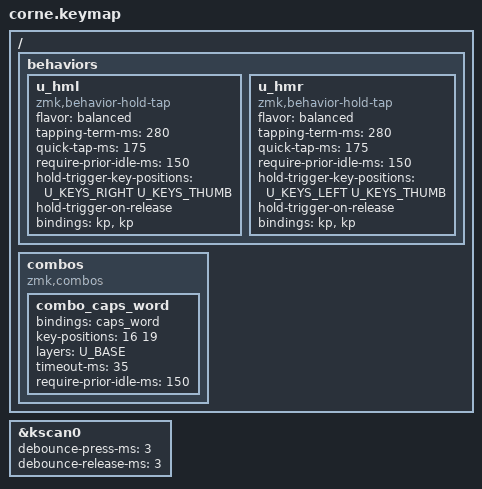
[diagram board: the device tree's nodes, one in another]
#include "../miryoku/custom_config.h"
#include "../miryoku/mapping/42/corne.h"
#include "../miryoku/miryoku.dtsi"

&kscan0 {
  debounce-press-ms = <3>;
  debounce-release-ms = <3>;
};

// Corne key positions, 42 keys, numbered from the top left.
//   0  1  2  3  4  5  |  6  7  8  9 10 11
//  12 13 14 15 16 17  | 18 19 20 21 22 23
//  24 25 26 27 28 29  | 30 31 32 33 34 35
//           36 37 38  | 39 40 41
#define U_KEYS_LEFT   0  1  2  3  4  5 12 13 14 15 16 17 24 25 26 27 28 29
#define U_KEYS_RIGHT  6  7  8  9 10 11 18 19 20 21 22 23 30 31 32 33 34 35
#define U_KEYS_THUMB 36 37 38 39 40 41

// Home-row mods, one behavior per hand. A mod only triggers if the next key is
// on the other hand or on a thumb, so a same-hand roll can never make a mod.
// This removes most false mods, which makes the longer tapping term safe.
// hold-trigger-on-release keeps same-hand mod combinations (such as Cmd+Shift)
// available if you hold both keys.
/ {
  behaviors {
    u_hml: u_hml {
      compatible = "zmk,behavior-hold-tap";
      #binding-cells = <2>;
      flavor = "balanced";
      tapping-term-ms = <280>;
      quick-tap-ms = <175>;
      require-prior-idle-ms = <150>;
      hold-trigger-key-positions = <U_KEYS_RIGHT U_KEYS_THUMB>;
      hold-trigger-on-release;
      bindings = <&kp>, <&kp>;
    };
    u_hmr: u_hmr {
      compatible = "zmk,behavior-hold-tap";
      #binding-cells = <2>;
      flavor = "balanced";
      tapping-term-ms = <280>;
      quick-tap-ms = <175>;
      require-prior-idle-ms = <150>;
      hold-trigger-key-positions = <U_KEYS_LEFT U_KEYS_THUMB>;
      hold-trigger-on-release;
      bindings = <&kp>, <&kp>;
    };
  };
};

// Caps Word combo: press the two home-row Shift keys, T (16) and N (19),
// together. Caps Word is also on the Nav layer, but this needs no layer hold.
// T and N are frequent letters and "nt" is a common bigram, so the guards are
// tight: both keys within 35 ms, and no key pressed in the last 150 ms. The
// idle rule is the same one the home-row mods use, so the combo cannot start in
// the middle of a word.
/ {
  combos {
    compatible = "zmk,combos";
    combo_caps_word {
      bindings = <&caps_word>;
      key-positions = <16 19>;
      layers = <U_BASE>;
      timeout-ms = <35>;
      require-prior-idle-ms = <150>;
    };
  };
};
